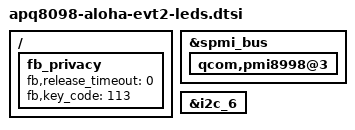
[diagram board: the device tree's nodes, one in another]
/* Copyright (c) 2017, Facebook Inc. All rights reserved.
 *
 * This program is free software; you can redistribute it and/or modify
 * it under the terms of the GNU General Public License version 2 and
 * only version 2 as published by the Free Software Foundation.
 *
 * This program is distributed in the hope that it will be useful,
 * but WITHOUT ANY WARRANTY; without even the implied warranty of
 * MERCHANTABILITY or FITNESS FOR A PARTICULAR PURPOSE.  See the
 * GNU General Public License for more details.
 */

#include <dt-bindings/leds/fb_led_control.h>

/*
 * This is a platform device for the camera status LED that
 * is controlled via TZ.
 */
/ {
	fb_privacy: fb_privacy {
		fb,release_timeout = <0>;
		fb,key_code = <113>;
	};

};

/* Delete led driver */
&spmi_bus {
	qcom,pmi8998@3 {
		/delete-node/ qcom,leds@d000;
	};
};

&i2c_6 {
	/delete-node/ tlc59116@69;
	/delete-node/ tlc59116@6A;
};

/* Delete smb driver */
/delete-node/ &smb138x;
